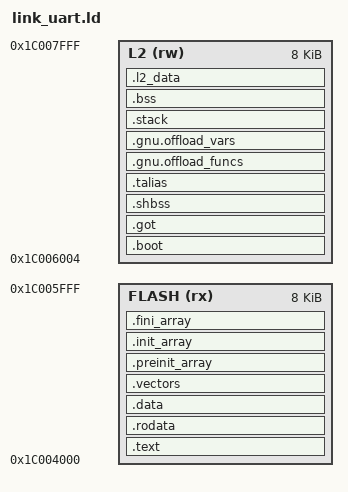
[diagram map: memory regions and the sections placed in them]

OUTPUT_ARCH(riscv)
ENTRY( _start )

MEMORY
{
  FLASH (rx)  : ORIGIN = 0x1c004000, LENGTH = 0x00002000
  L2 (rw)     : ORIGIN = 0x1c006004, LENGTH = 0x00001ffc
}

SECTIONS
{
  .text MAX(0x1c004000,ALIGN(4)) :
  {
    . = ALIGN(4);
    _stext = .;
    *(.text)
    *(.text.*)
    _etext  =  .;
    *(.lit)
    *(.shdata)
    _endtext = .;
    . = ALIGN(4);
  } > FLASH

  .rodata : {
    . = ALIGN(4);
    *(.rodata);
    *(.rodata.*)
    *(.srodata);
    *(.srodata.*)
    *(.eh_frame*)
    _endrodata = .;
  } > FLASH

  .boot : {
    . = ALIGN(4);
    *(.boot)
    *(.boot.data)
  } > L2

  .got : {
    . = ALIGN(4);
    *(.got.plt) * (.igot.plt) *(.got) *(.igot)
  } > L2

  .shbss : {
    . = ALIGN(4);
    *(.shbss)
  } > L2


  .talias : {
  } > L2


  .gnu.offload_funcs : {
    . = ALIGN(4);
    KEEP(*(.gnu.offload_funcs))
  } > L2


  .gnu.offload_vars : {
    . = ALIGN(4);
    KEEP(*(.gnu.offload_vars))
  } > L2


  .stack : {
    . = ALIGN(4);
    . = ALIGN(16);
    stack_start = .;
    . = . + 0x800;
    stack = .;
  } > L2


  .data : {
    . = ALIGN(4);
    sdata  =  .;
    _sdata  =  .;
    *(.data_fc)
    *(.data_fc.*)
    *(.data);
    *(.data.*)
    *(.sdata);
    *(.sdata.*)
    *(.heapl2ram)
    *(.fcTcdm)
    *(.fcTcdm.*)
    *(.fcTcdm_g)
    *(.fcTcdm_g.*)
    . = ALIGN(4);
    edata  =  .;
    _edata  =  .;
  } > FLASH


  .bss : {
    . = ALIGN(8);
    _bss_start = .;
    *(.bss)
    *(.bss.*)
    *(.sbss)
    *(.sbss.*)
    *(COMMON)
    . = ALIGN(4);
    _bss_end = .;
  } > L2


  __l2_priv0_end = ALIGN(4);

  .vectors :
  {
    __irq_vector_base = .;
    KEEP(*(.vectors))
  } > FLASH

  __l2_priv1_end = ALIGN(4);

  .preinit_array : {
    . = ALIGN(4);
    PROVIDE_HIDDEN (__preinit_array_start = .);
    KEEP (*(.preinit_array))
    PROVIDE_HIDDEN (__preinit_array_end = .);
  } > FLASH

  .init_array : {
    . = ALIGN(4);
    PROVIDE_HIDDEN (__init_array_start = .);
    __CTOR_LIST__ = .;
    LONG((__CTOR_END__ - __CTOR_LIST__) / 4 - 2)
    KEEP(*(.ctors.start))
    KEEP(*(.ctors))
    KEEP (*(SORT(.init_array.*)))
    KEEP (*(.init_array ))
    LONG(0)
    __CTOR_END__ = .;
    PROVIDE_HIDDEN (__init_array_end = .);
  } > FLASH

  .fini_array : {
    . = ALIGN(4);
    PROVIDE_HIDDEN (__fini_array_start = .);
    __DTOR_LIST__ = .;
    LONG((__DTOR_END__ - __DTOR_LIST__) / 4 - 2)
    KEEP(*(.dtors.start))
    KEEP(*(.dtors))
    LONG(0)
    __DTOR_END__ = .;
    KEEP (*(SORT(.fini_array.*)))
    KEEP (*(.fini_array ))
    PROVIDE_HIDDEN (__fini_array_end = .);
  } > FLASH

  .l2_data :
  {
    . = ALIGN(4);
    __cluster_text_start = .;
    *(.cluster.text)
    *(.cluster.text.*)
    . = ALIGN(4);
    __cluster_text_end = .;
    *(.l2_data)
    *(.l2_data.*)
    *(.data_fc_shared)
    *(.data_fc_shared.*)
    . = ALIGN(4);
  } > L2

  __l2_shared_end = .;
}
